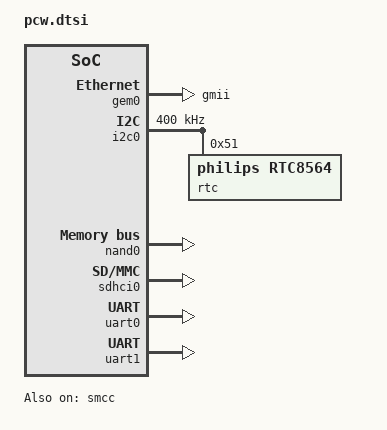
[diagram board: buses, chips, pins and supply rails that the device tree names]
/*
 * CAUTION: This file is automatically generated by Xilinx.
 * Version:  
 * Today is: Wed Jan 16 01:01:24 2019
 */


/ {
	cpus {
		cpu@0 {
			operating-points = <666666 1000000 333333 1000000>;
		};
	};
};
&gem0 {
	phy-mode = "gmii";
	status = "okay";
	xlnx,ptp-enet-clock = <0x69f6bcb>;
};
&gpio0 {
	emio-gpio-width = <64>;
	gpio-mask-high = <0x0>;
	gpio-mask-low = <0x5600>;
};
&i2c0 {
	clock-frequency = <400000>;
	status = "okay";
	rtc@51 {
		compatible = "philips,rtc8564";
		#address-cells = <0x1>;
		#size-cells = <0x0>;
		reg = <0x51>;
	};
};
&intc {
	num_cpus = <2>;
	num_interrupts = <96>;
};
&nand0 {
	arm,nand-cycle-t0 = <0x2>;
	arm,nand-cycle-t1 = <0x2>;
	arm,nand-cycle-t2 = <0x1>;
	arm,nand-cycle-t3 = <0x1>;
	arm,nand-cycle-t4 = <0x1>;
	arm,nand-cycle-t5 = <0x1>;
	arm,nand-cycle-t6 = <0x1>;
	status = "okay";
};
&sdhci0 {
	status = "okay";
	xlnx,has-cd = <0x0>;
	xlnx,has-power = <0x0>;
	xlnx,has-wp = <0x0>;
};
&smcc {
	status = "okay";
};
&uart0 {
	device_type = "serial";
	port-number = <0>;
	status = "okay";
};
&uart1 {
	device_type = "serial";
	port-number = <1>;
	status = "okay";
};
&clkc {
	fclk-enable = <0x7>;
	ps-clk-frequency = <33333333>;
};
